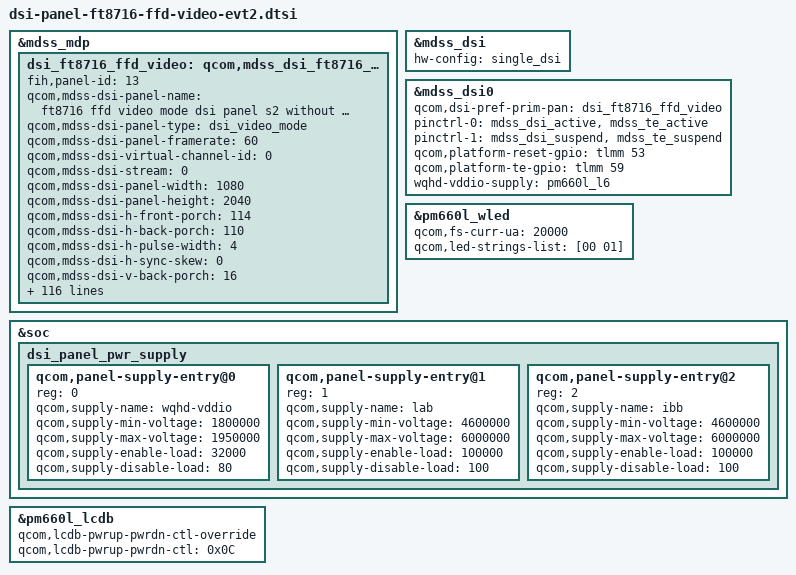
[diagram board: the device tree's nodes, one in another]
/* Copyright (c) 2015, The Linux Foundation. All rights reserved.
 *
 * This program is free software; you can redistribute it and/or modify
 * it under the terms of the GNU General Public License version 2 and
 * only version 2 as published by the Free Software Foundation.
 *
 * This program is distributed in the hope that it will be useful,
 * but WITHOUT ANY WARRANTY; without even the implied warranty of
 * MERCHANTABILITY or FITNESS FOR A PARTICULAR PURPOSE.  See the
 * GNU General Public License for more details.
 */

/*---------------------------------------------------------------------------
 * Templated from dsi-panel-r69006-1080p-video.dtsi
 *---------------------------------------------------------------------------*/
&mdss_mdp {
	dsi_ft8716_ffd_video: qcom,mdss_dsi_ft8716_ffd_video_s2 {
		fih,panel-id = <13>;
		qcom,mdss-dsi-panel-name = "ft8716 ffd video mode dsi panel s2 without DSC";
		qcom,mdss-dsi-panel-type = "dsi_video_mode";
		qcom,mdss-dsi-panel-framerate = <60>;
		qcom,mdss-dsi-virtual-channel-id = <0>;
		qcom,mdss-dsi-stream = <0>;
		qcom,mdss-dsi-panel-width = <1080>;
		qcom,mdss-dsi-panel-height = <2040>;
		qcom,mdss-dsi-h-front-porch = <114>;
		qcom,mdss-dsi-h-back-porch = <110>;
		qcom,mdss-dsi-h-pulse-width = <4>;
		qcom,mdss-dsi-h-sync-skew = <0>;
		qcom,mdss-dsi-v-back-porch = <16>;
		qcom,mdss-dsi-v-front-porch = <16>;
		qcom,mdss-dsi-v-pulse-width = <2>;
		qcom,mdss-dsi-h-left-border = <0>;
		qcom,mdss-dsi-h-right-border = <0>;
		qcom,mdss-dsi-v-top-border = <0>;
		qcom,mdss-dsi-v-bottom-border = <0>;
		qcom,mdss-dsi-bpp = <24>;
		qcom,mdss-dsi-underflow-color = <0xff>;
		qcom,mdss-dsi-border-color = <0>;
		qcom,mdss-dsi-on-command = [
			// ENABLE CMD2
			29 00 00 00 00 00 04 FF 87 16 01
			29 00 00 00 00 00 02 00 80
			29 01 00 00 00 00 03 FF 87 16
			// Config WA
			29 00 00 00 00 00 02 00 80
			29 01 00 00 00 00 0D D8 80 81 82 83 85 87 89 8b 8b 8a 89 88
			29 00 00 00 00 00 02 00 90
			29 01 00 00 00 00 0D D8 00 02 02 03 04 05 06 08 06 06 06 04
			29 00 00 00 00 00 02 00 A0
			29 01 00 00 00 00 0D D8 00 00 00 00 80 81 81 81 00 01 02 04
			29 00 00 00 00 00 02 00 B0
			29 01 00 00 00 00 0D D8 00 00 80 80 81 81 82 83 85 87 87 89
			29 00 00 00 00 00 02 00 C0
			29 01 00 00 00 00 0D D8 85 8d 91 97 a2 ad b9 c3 cd d3 d3 d6
			29 00 00 00 00 00 02 00 D0
			29 01 00 00 00 00 0D D8 02 05 07 0a 0e 12 16 1b 1e 1e 1e 1f
			29 00 00 00 00 00 02 00 E0
			29 01 00 00 00 00 04 D8 fc fb e9
			29 00 00 00 00 00 02 00 C0
			29 01 00 00 00 00 02 D7 41
			// DGAMMA OFF
			29 01 00 00 00 00 02 00 A0
			29 01 00 00 00 00 02 D7 05
			// CE
			29 00 00 00 00 00 02 00 A0
			29 01 00 00 00 00 0D D6 0f 0f 0f 0f 0f 0f 0f 0f 0f 0f 0f 0f
			29 00 00 00 00 00 02 00 B0
			29 01 00 00 00 00 0D D6 80 80 cd cd cd cd cd cd cd cd cd cd
			29 00 00 00 00 00 02 00 C0
			29 01 00 00 00 00 0D D6 80 80 b3 b3 b3 b3 b3 b3 b3 b3 b3 b3
			29 00 00 00 00 00 02 00 D0
			29 01 00 00 00 00 0D D6 80 80 9a 9a 9a 9a 9a 9a 9a 9a 9a 9a
			// AIE V3
			29 00 00 00 00 00 02 00 01
			29 00 00 00 00 00 02 C6 10
			29 00 00 00 00 00 02 00 00
			29 01 00 00 00 00 13 C8 90 78 56 34 33 33 33 33 33 33 43 44 43 44 44 44 44 54
			29 00 00 00 00 00 02 00 01
			29 00 00 00 00 00 02 C6 11
			29 00 00 00 00 00 02 00 00
			29 01 00 00 00 00 13 C8 90 78 56 34 33 33 22 33 33 43 44 44 43 44 44 44 44 54
			29 00 00 00 00 00 02 00 01
			29 00 00 00 00 00 02 C6 12
			29 00 00 00 00 00 02 00 00
			29 01 00 00 00 00 13 C8 E0 8C 56 33 33 33 33 33 33 33 23 22 33 43 44 44 44 44
			29 00 00 00 00 00 02 00 01
			29 00 00 00 00 00 02 C6 00
			// AIE CONFIG
			29 00 00 00 00 00 02 00 00
			29 01 00 00 00 00 02 92 00	// CMD_44
			// Select White Point CT / BLF
			29 00 00 00 00 00 02 00 00
			29 01 00 00 00 00 02 94 C4	// CMD_46
			// CE CONFIG
			29 00 00 00 00 00 02 00 00
			29 01 00 00 00 00 02 91 80      // CMD_48
			// DISABLE CMD2
			29 00 00 00 00 00 02 00 00
			29 01 00 00 00 00 04 FF 00 00 00
			// ??
			29 00 00 00 00 00 02 00 80
			29 00 00 00 00 00 03 FF 00 00
			// DSI ON
			05 01 00 00 78 00 02 11 00
			05 01 00 00 0a 00 02 35 00
			05 01 00 00 00 00 02 29 00
		];
		qcom,mdss-dsi-off-command = [05 01 00 00 14 00 02 28 00
				 05 01 00 00 78 00 02 10 00];
		qcom,mdss-dsi-on-command-state = "dsi_lp_mode";
		qcom,mdss-dsi-off-command-state = "dsi_hs_mode";
		qcom,mdss-dsi-h-sync-pulse = <0>;
		qcom,mdss-dsi-traffic-mode = "non_burst_sync_event";
		qcom,mdss-dsi-bllp-eof-power-mode;
		qcom,mdss-dsi-bllp-power-mode;
		qcom,mdss-dsi-lane-0-state;
		qcom,mdss-dsi-lane-1-state;
		qcom,mdss-dsi-lane-2-state;
		qcom,mdss-dsi-lane-3-state;
		qcom,mdss-dsi-t-clk-post = <0x0d>;
		qcom,mdss-dsi-t-clk-pre = <0x2d>;
		qcom,esd-check-enabled;
		qcom,mdss-dsi-panel-status-check-mode = "reg_read";
		qcom,mdss-dsi-panel-status-command = [06 01 00 01 00 00 01 0a
		06 01 00 01 00 00 01 0b
		06 01 00 01 00 00 01 0c
		06 01 00 01 00 00 01 0d
		06 01 00 01 00 00 01 0e];
		qcom,mdss-dsi-panel-status-command-state = "dsi_hs_mode";
		qcom,mdss-dsi-panel-status-value = <0x9c>,<0x00>,<0x07>,<0x00>,<0x80>;
		qcom,mdss-dsi-panel-on-check-value = <0x9c>,<0x00>,<0x07>,<0x00>,<0x80>;
		qcom,mdss-dsi-panel-status-read-length = <1>,<1>,<1>,<1>,<1>;
		qcom,mdss-dsi-panel-max-error-count = <3>;
		qcom,mdss-dsi-dma-trigger = "trigger_sw";
		qcom,mdss-dsi-mdp-trigger = "none";
		qcom,mdss-dsi-reset-sequence = <1 1>, <0 1>, <1 15>;

		// dynamic : value 1
		qcom,mdss-dsi-ce-on-command = [
			29 01 00 00 00 00 03 91 80 00
		];

		qcom,mdss-dsi-ce-on-command-test1 = [
			29 01 00 00 00 00 03 91 C0 00
		];

		qcom,mdss-dsi-ce-on-command-test2 = [
			29 01 00 00 00 00 03 91 FF 00
		];

		// standard : value 0
		qcom,mdss-dsi-ce-off-command = [
			29 01 00 00 00 00 03 91 00 00
		];

		qcom,mdss-dsi-ct-normal-command = [
			// Enable CMD2
			29 00 00 00 00 00 04 FF 87 16 01
			29 00 00 00 00 00 02 00 80
			29 01 00 00 00 00 03 FF 87 16
			// Gamma Channel
			29 00 00 00 00 00 02 00 A0
			29 01 00 00 00 00 02 D7 05
			// Select White Point
			29 00 00 00 00 00 02 00 00
			29 01 00 00 00 00 02 94 C4
			// Disable CMD2
			29 00 00 00 00 00 02 00 00
			29 00 00 00 00 00 04 FF 00 00 00
			29 00 00 00 00 00 02 00 80
			29 01 00 00 00 00 03 FF 00 00
		];

		qcom,mdss-dsi-ct-warm-command = [
			// Enable CMD2
			29 00 00 00 00 00 04 FF 87 16 01
			29 00 00 00 00 00 02 00 80
			29 01 00 00 00 00 03 FF 87 16
			// Gamma Channel
			29 00 00 00 00 00 02 00 A0
			29 01 00 00 00 00 02 D7 05
			// Select White Point
			29 00 00 00 00 00 02 00 00
			29 01 00 00 00 00 02 94 CD
			// Disable CMD2
			29 00 00 00 00 00 02 00 00
			29 00 00 00 00 00 04 FF 00 00 00
			29 00 00 00 00 00 02 00 80
			29 01 00 00 00 00 03 FF 00 00
		];

		qcom,mdss-dsi-ct-cold-command = [
			// Enable CMD2
			29 00 00 00 00 00 04 FF 87 16 01
			29 00 00 00 00 00 02 00 80
			29 01 00 00 00 00 03 FF 87 16
			// Gamma Channel
			29 00 00 00 00 00 02 00 A0
			29 01 00 00 00 00 02 D7 05
			// Select White Point
			29 00 00 00 00 00 02 00 00
			29 01 00 00 00 00 02 94 C0
			// Disable CMD2
			29 00 00 00 00 00 02 00 00
			29 00 00 00 00 00 04 FF 00 00 00
			29 00 00 00 00 00 02 00 80
			29 01 00 00 00 00 03 FF 00 00
		];

		qcom,mdss-dsi-blf-10-command = [
			// Enable CMD2
			29 00 00 00 00 00 04 FF 87 16 01
			29 00 00 00 00 00 02 00 80
			29 01 00 00 00 00 03 FF 87 16
			// Gamma Channel
			29 00 00 00 00 00 02 00 A0
			29 01 00 00 00 00 02 D7 05
			// Select White Point
			29 00 00 00 00 00 02 00 00
			29 01 00 00 00 00 02 94 C8
			// Disable CMD2
			29 00 00 00 00 00 02 00 00
			29 00 00 00 00 00 04 FF 00 00 00
			29 00 00 00 00 00 02 00 80
			29 01 00 00 00 00 03 FF 00 00
		];

		qcom,mdss-dsi-blf-30-command = [
			// Enable CMD2
			29 00 00 00 00 00 04 FF 87 16 01
			29 00 00 00 00 00 02 00 80
			29 01 00 00 00 00 03 FF 87 16
			// Gamma Channel
			29 00 00 00 00 00 02 00 A0
			29 01 00 00 00 00 02 D7 05
			// Select White Point
			29 00 00 00 00 00 02 00 00
			29 01 00 00 00 00 02 94 D5
			// Disable CMD2
			29 00 00 00 00 00 02 00 00
			29 00 00 00 00 00 04 FF 00 00 00
			29 00 00 00 00 00 02 00 80
			29 01 00 00 00 00 03 FF 00 00
		];

		qcom,mdss-dsi-blf-50-command = [
			// Enable CMD2
			29 00 00 00 00 00 04 FF 87 16 01
			29 00 00 00 00 00 02 00 80
			29 01 00 00 00 00 03 FF 87 16
			// Gamma Channel
			29 00 00 00 00 00 02 00 A0
			29 01 00 00 00 00 02 D7 05
			// Select White Point
			29 00 00 00 00 00 02 00 00
			29 01 00 00 00 00 02 94 E9
			// Disable CMD2
			29 00 00 00 00 00 02 00 00
			29 00 00 00 00 00 04 FF 00 00 00
			29 00 00 00 00 00 02 00 80
			29 01 00 00 00 00 03 FF 00 00
		];

		qcom,mdss-dsi-blf-75-command = [
			// Enable CMD2
			29 00 00 00 00 00 04 FF 87 16 01
			29 00 00 00 00 00 02 00 80
			29 01 00 00 00 00 03 FF 87 16
			// Gamma Channel
			29 00 00 00 00 00 02 00 A0
			29 01 00 00 00 00 02 D7 05
			// Select White Point
			29 00 00 00 00 00 02 00 00
			29 01 00 00 00 00 02 94 FF
			// Disable CMD2
			29 00 00 00 00 00 02 00 00
			29 00 00 00 00 00 04 FF 00 00 00
			29 00 00 00 00 00 02 00 80
			29 01 00 00 00 00 03 FF 00 00
		];

		// AIE
		qcom,mdss-dsi-aie-off-command = [
			// ENABLE CMD2
			29 00 00 00 00 00 02 00 00
			29 00 00 00 00 00 04 FF 87 16 01
			29 00 00 00 00 00 02 00 80
			29 01 00 00 00 00 03 FF 87 16
			// AIE OFF
			29 00 00 00 00 00 02 00 00
			29 01 00 00 00 00 02 92 00
			// DISABLE CMD2
			29 00 00 00 00 00 02 00 00
			29 00 00 00 00 00 04 FF 00 00 00
			29 00 00 00 00 00 02 00 80
			29 01 00 00 00 00 03 FF 00 00
		];

		qcom,mdss-dsi-aie-low-command = [
			// ENABLE CMD2
			29 00 00 00 00 00 02 00 00
			29 00 00 00 00 00 04 FF 87 16 01
			29 00 00 00 00 00 02 00 80
			29 01 00 00 00 00 03 FF 87 16
			// AIE OFF
			29 00 00 00 00 00 02 00 00
			29 01 00 00 00 00 02 92 80
			// DISABLE CMD2
			29 00 00 00 00 00 02 00 00
			29 00 00 00 00 00 04 FF 00 00 00
			29 00 00 00 00 00 02 00 80
			29 01 00 00 00 00 03 FF 00 00
		];

		qcom,mdss-dsi-aie-mid-command = [
			// ENABLE CMD2
			29 00 00 00 00 00 02 00 00
			29 00 00 00 00 00 04 FF 87 16 01
			29 00 00 00 00 00 02 00 80
			29 01 00 00 00 00 03 FF 87 16
			// AIE OFF
			29 00 00 00 00 00 02 00 00
			29 01 00 00 00 00 02 92 81
			// DISABLE CMD2
			29 00 00 00 00 00 02 00 00
			29 00 00 00 00 00 04 FF 00 00 00
			29 00 00 00 00 00 02 00 80
			29 01 00 00 00 00 03 FF 00 00
		];

		qcom,mdss-dsi-aie-high-command = [
			// ENABLE CMD2
			29 00 00 00 00 00 02 00 00
			29 00 00 00 00 00 04 FF 87 16 01
			29 00 00 00 00 00 02 00 80
			29 01 00 00 00 00 03 FF 87 16
			// AIE OFF
			29 00 00 00 00 00 02 00 00
			29 01 00 00 00 00 02 92 82
			// DISABLE CMD2
			29 00 00 00 00 00 02 00 00
			29 00 00 00 00 00 04 FF 00 00 00
			29 00 00 00 00 00 02 00 80
			29 01 00 00 00 00 03 FF 00 00
		];

		//qcom,mdss-dsi-cabc-off-command = [
		//	15 01 00 00 05 00 02 55 00
		//];

		//qcom,mdss-dsi-cabc-ui-command = [
		//	15 01 00 00 05 00 02 55 01
		//];

		//qcom,mdss-dsi-cabc-still-command = [
		//	15 01 00 00 05 00 02 55 02
		//];

		//qcom,mdss-dsi-cabc-moving-command = [
		//	15 01 00 00 05 00 02 55 03
		//];

		qcom,mdss-dsi-ce-on-command-state = "dsi_hs_mode";
		qcom,mdss-dsi-ce-on-command-state-test1 = "dsi_hs_mode";
		qcom,mdss-dsi-ce-on-command-state-test2 = "dsi_hs_mode";
		qcom,mdss-dsi-ce-off-command-state = "dsi_hs_mode";

		qcom,mdss-dsi-ct-normal-command-state = "dsi_lp_mode";
		qcom,mdss-dsi-ct-warm-command-state = "dsi_lp_mode";
		qcom,mdss-dsi-ct-cold-command-state = "dsi_lp_mode";

		qcom,mdss-dsi-blf-10-command-state = "dsi_lp_mode";
		qcom,mdss-dsi-blf-30-command-state = "dsi_lp_mode";
		qcom,mdss-dsi-blf-50-command-state = "dsi_lp_mode";
		qcom,mdss-dsi-blf-75-command-state = "dsi_lp_mode";

		qcom,mdss-dsi-aie-off-command-state = "dsi_lp_mode";
		qcom,mdss-dsi-aie-low-command-state = "dsi_lp_mode";
		qcom,mdss-dsi-aie-mid-command-state = "dsi_lp_mode";
		qcom,mdss-dsi-aie-high-command-state = "dsi_lp_mode";

		//qcom,mdss-dsi-cabc-off-command-state = "dsi_hs_mode";
		//qcom,mdss-dsi-cabc-ui-command-state = "dsi_hs_mode";
		//qcom,mdss-dsi-cabc-still-command-state = "dsi_hs_mode";
		//qcom,mdss-dsi-cabc-moving-command-state = "dsi_hs_mode";

		qcom,mdss-pan-physical-width-dimension = <65>;
		qcom,mdss-pan-physical-height-dimension = <123>;
	};
};

&dsi_ft8716_ffd_video {
	// 853 Mbps
	qcom,mdss-dsi-panel-timings-phy-v2 = [
		23 1f 07 09 05 03 04 a0
		23 1f 07 09 05 03 04 a0
		23 1f 07 09 05 03 04 a0
		23 1f 07 09 05 03 04 a0
		23 19 08 08 05 03 04 a0];

	// 976 Mbps (for RF desense)
	qcom,mdss-dsi-panel-timings-phy-v2-976 = [
		25 1F 09 0A 06 03 04 a0
		25 1F 09 0A 06 03 04 a0
		25 1F 09 0A 06 03 04 a0
		25 1F 09 0A 06 03 04 a0
		25 1E 08 0A 06 03 04 a0];

	// 912 Mbps (for RF desense)
	qcom,mdss-dsi-panel-timings-phy-v2-912 = [
		24 1f 08 09 05 03 04 a0
		24 1f 08 09 05 03 04 a0
		24 1f 08 09 05 03 04 a0
		24 1f 08 09 05 03 04 a0
		24 1b 08 09 05 03 04 a0];

	qcom,mdss-dsi-bl-pmic-control-type = "bl_ctrl_wled";
	qcom,mdss-dsi-bl-min-level = <1>;
	qcom,mdss-dsi-bl-max-level = <4095>;
	qcom,panel-supply-entries = <&dsi_panel_pwr_supply>;
};

&mdss_dsi {
	hw-config = "single_dsi";
};

&mdss_dsi0 {
	qcom,dsi-pref-prim-pan = <&dsi_ft8716_ffd_video>;
	pinctrl-names = "mdss_default", "mdss_sleep";
	pinctrl-0 = <&mdss_dsi_active &mdss_te_active>;
	pinctrl-1 = <&mdss_dsi_suspend &mdss_te_suspend>;
	qcom,platform-reset-gpio = <&tlmm 53 0>;
	qcom,platform-te-gpio = <&tlmm 59 0>;
	wqhd-vddio-supply = <&pm660l_l6>;
};

&pm660l_wled {
	qcom,fs-curr-ua = <20000>;
	qcom,led-strings-list = [00 01];
};

&soc {
	/delete-node/ dsi_panel_pwr_supply;
	dsi_panel_pwr_supply: dsi_panel_pwr_supply {
		#address-cells = <1>;
		#size-cells = <0>;

		qcom,panel-supply-entry@0 {
			reg = <0>;
			qcom,supply-name = "wqhd-vddio";
			qcom,supply-min-voltage = <1800000>;
			qcom,supply-max-voltage = <1950000>;
			qcom,supply-enable-load = <32000>;
			qcom,supply-disable-load = <80>;
		};

		qcom,panel-supply-entry@1 {
			reg = <1>;
			qcom,supply-name = "lab";
			qcom,supply-min-voltage = <4600000>;
			qcom,supply-max-voltage = <6000000>;
			qcom,supply-enable-load = <100000>;
			qcom,supply-disable-load = <100>;
		};

		qcom,panel-supply-entry@2 {
			reg = <2>;
			qcom,supply-name = "ibb";
			qcom,supply-min-voltage = <4600000>;
			qcom,supply-max-voltage = <6000000>;
			qcom,supply-enable-load = <100000>;
			qcom,supply-disable-load = <100>;
		};
	};
};

&pm660l_lcdb {
	qcom,lcdb-pwrup-pwrdn-ctl-override;
	qcom,lcdb-pwrup-pwrdn-ctl = /bits/ 8 <0x0C>;
};
